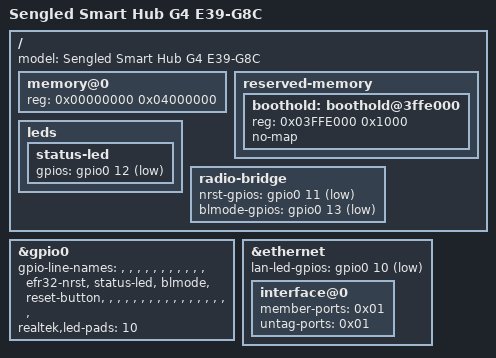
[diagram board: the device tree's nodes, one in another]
// SPDX-License-Identifier: GPL-2.0
#include "rtl8196e.dts"

/ {
	model = "Sengled Smart Hub G4 E39-G8C";

	memory@0 {
		device_type = "memory";
		reg = <0x00000000 0x04000000>;  /* 64MB */
	};

	reserved-memory {
		/delete-node/ boothold@1ffe000;

		/* Re-declare the boothold: label on the relocated node — the
		 * base rtl8196e.dts carries it on the node deleted just above,
		 * so a phandle to &boothold would otherwise name a page this
		 * board does not reserve. Nothing takes it that way today: the
		 * userspace tool looks the node up by name at runtime, and the
		 * bootloader has the address compiled in. */
		boothold: boothold@3ffe000 {
			reg = <0x03FFE000 0x1000>;  /* 4KB reserved for boothold flag (high DRAM, just below btcode stack) */
			no-map;
		};
	};

	leds {
		status-led {
			gpios = <&gpio0 12 GPIO_ACTIVE_LOW>;
		};

	};

	radio-bridge {
		nrst-gpios = <&gpio0 11 (GPIO_ACTIVE_LOW | GPIO_OPEN_DRAIN)>;
		blmode-gpios = <&gpio0 13 (GPIO_ACTIVE_LOW | GPIO_OPEN_DRAIN)>;
		/* The G4 does not wire RTS/CTS. This dts #includes rtl8196e.dts,
		 * which declares realtek,hw-flow-control on this node, so delete
		 * it here: the bridge then reports the board as not hw-capable
		 * and defaults flow_control to sw. */
		/delete-property/ realtek,hw-flow-control;
	};
};

&gpio0 {
	gpio-line-names =
		"", "", "", "", "", "", "", "",			/* A0-A7  */
		"", "", "", "efr32-nrst",			/* B0-B3  */
		"status-led", "blmode", "reset-button", "",	/* B4-B7  */
		"", "", "", "", "", "", "", "",			/* C0-C7  */
		"", "", "", "", "", "", "", "";			/* D0-D7  */

	/* Port-0 LAN LED on B2/LED_PORT0 (#126).  Overrides the inherited
	 * Lidl value (B6 — named reset-button on this board): the LED pad
	 * is a per-board wiring fact. */
	realtek,led-pads = <10>;			/* B2: LAN LED */
};

/* Ethernet configuration */
&ethernet {
	/* Override the inherited Lidl B6 wiring: G4 LAN LED is B2/LED_PORT0. */
	lan-led-gpios = <&gpio0 10 GPIO_ACTIVE_LOW>;

	interface@0 {
		member-ports = <0x01>;      /* Port mask: 0x01 = port 0 (bit 0 set) */
		untag-ports = <0x01>;       /* Untagged port mask: port 0 untagged */
	};

};
